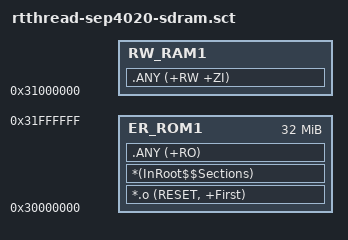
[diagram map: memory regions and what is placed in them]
; *************************************************************
; *** Scatter-Loading Description File generated by uVision ***
; *************************************************************

LR_ROM1 0x30000000 0x02000000  {    ; load region size_region
  ER_ROM1 0x30000000 0x02000000  {  ; load address = execution address
   *.o (RESET, +First)
   *(InRoot$$Sections)
   .ANY (+RO)
   }
   RW_RAM1 0x31000000{
   .ANY (+RW +ZI)
  }
}

